# ESP32-S3 register map
Vendor: ESPRESSIF SYSTEMS (SHANGHAI) CO., LTD.; Series: ESP32 S-Series; File version: 22
CPU: Xtensa LX7 r0p0, little endian, no MPU, FPU, 0 interrupt priority bits
Address unit: 32 bits
Registers are 32-bit, read-write, reset 0x0 unless marked. A register's access mark holds for its fields unless they carry their own. Offsets are from the block's base; [hi:lo] are bit positions; {n}, {i} and the like mark numbered series.

## WCL — WCL Peripheral
Base 0x600D0000
0x00 Core_0_ENTRY_1_ADDR — Core_0 Entry 1 address configuration Register
  [31:0] CORE_0_ENTRY_1_ADDR — Core_0 Entry 1 address from WORLD1 to WORLD0
0x04 Core_0_ENTRY_2_ADDR — Core_0 Entry 2 address configuration Register
  [31:0] CORE_0_ENTRY_2_ADDR — Core_0 Entry 2 address from WORLD1 to WORLD0
0x08 Core_0_ENTRY_3_ADDR — Core_0 Entry 3 address configuration Register
  [31:0] CORE_0_ENTRY_3_ADDR — Core_0 Entry 3 address from WORLD1 to WORLD0
0x0C Core_0_ENTRY_4_ADDR — Core_0 Entry 4 address configuration Register
  [31:0] CORE_0_ENTRY_4_ADDR — Core_0 Entry 4 address from WORLD1 to WORLD0
0x10 Core_0_ENTRY_5_ADDR — Core_0 Entry 5 address configuration Register
  [31:0] CORE_0_ENTRY_5_ADDR — Core_0 Entry 5 address from WORLD1 to WORLD0
0x14 Core_0_ENTRY_6_ADDR — Core_0 Entry 6 address configuration Register
  [31:0] CORE_0_ENTRY_6_ADDR — Core_0 Entry 6 address from WORLD1 to WORLD0
0x18 Core_0_ENTRY_7_ADDR — Core_0 Entry 7 address configuration Register
  [31:0] CORE_0_ENTRY_7_ADDR — Core_0 Entry 7 address from WORLD1 to WORLD0
0x1C Core_0_ENTRY_8_ADDR — Core_0 Entry 8 address configuration Register
  [31:0] CORE_0_ENTRY_8_ADDR — Core_0 Entry 8 address from WORLD1 to WORLD0
0x20 Core_0_ENTRY_9_ADDR — Core_0 Entry 9 address configuration Register
  [31:0] CORE_0_ENTRY_9_ADDR — Core_0 Entry 9 address from WORLD1 to WORLD0
0x24 Core_0_ENTRY_10_ADDR — Core_0 Entry 10 address configuration Register
  [31:0] CORE_0_ENTRY_10_ADDR — Core_0 Entry 10 address from WORLD1 to WORLD0
0x28 Core_0_ENTRY_11_ADDR — Core_0 Entry 11 address configuration Register
  [31:0] CORE_0_ENTRY_11_ADDR — Core_0 Entry 11 address from WORLD1 to WORLD0
0x2C Core_0_ENTRY_12_ADDR — Core_0 Entry 12 address configuration Register
  [31:0] CORE_0_ENTRY_12_ADDR — Core_0 Entry 12 address from WORLD1 to WORLD0
0x30 Core_0_ENTRY_13_ADDR — Core_0 Entry 13 address configuration Register
  [31:0] CORE_0_ENTRY_13_ADDR — Core_0 Entry 13 address from WORLD1 to WORLD0
0x7C Core_0_ENTRY_CHECK reset 0x2 — Core_0 Entry check configuration Register
  [13:1] CORE_0_ENTRY_CHECK — This filed is used to enable entry address check
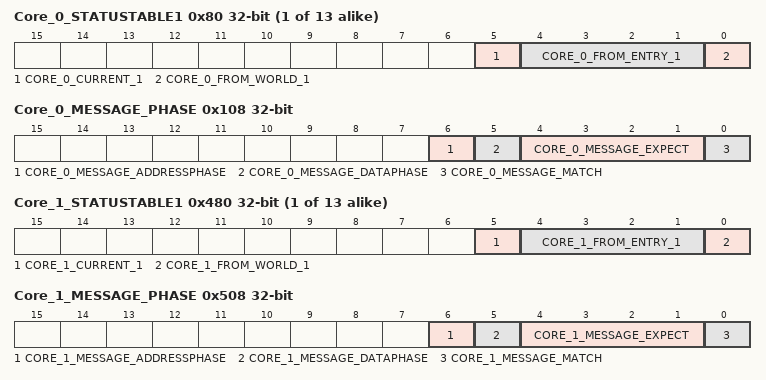
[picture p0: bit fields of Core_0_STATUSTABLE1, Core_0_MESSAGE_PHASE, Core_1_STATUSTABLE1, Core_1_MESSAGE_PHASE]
{0x7C+4i} Core_0_STATUSTABLE{i} (i=1..13) — Status register of world switch of entry {i}
  [5] CORE_0_CURRENT_{i} — This bit is used to confirm whether the current state is in entry {i}
  [4:1] CORE_0_FROM_ENTRY_{i} — This filed is used to confirm in which entry before enter entry {i}
  [0] CORE_0_FROM_WORLD_{i} — This bit is used to confirm world before enter entry {i}
0xFC Core_0_STATUSTABLE_CURRENT — Status register of statustable current
  [13:1] CORE_0_STATUSTABLE_CURRENT — This field is used to quickly read and rewrite the current field of all STATUSTABLE registers,for example,bit 1 represents the current field of STATUSTABLE1,bit2 represents the current field of STATUSTABLE2
0x100 Core_0_MESSAGE_ADDR — Clear writer_buffer write address configuration register
  [31:0] CORE_0_MESSAGE_ADDR — This field is used to set address that need to write when enter WORLD0
0x104 Core_0_MESSAGE_MAX — Clear writer_buffer write number configuration register
  [3:0] CORE_0_MESSAGE_MAX — This filed is used to set the max value of clear write_buffer
0x108 Core_0_MESSAGE_PHASE ro — Clear writer_buffer status register
  [6] CORE_0_MESSAGE_ADDRESSPHASE — If this bit is 1, it means that is checking clear write_buffer operation,and is checking address.
  [5] CORE_0_MESSAGE_DATAPHASE — If this bit is 1, it means that is checking clear write_buffer operation,and is checking data
  [4:1] CORE_0_MESSAGE_EXPECT — This field indicates the data to be written next time
  [0] CORE_0_MESSAGE_MATCH — This bit indicates whether the check is successful
0x140 Core_0_World_TRIGGER_ADDR — Core_0 trigger address configuration Register
  [31:0] CORE_0_WORLD_TRIGGER_ADDR — This field is used to configure the entry address from WORLD0 to WORLD1,when the CPU executes to this address,switch to WORLD1
0x144 Core_0_World_PREPARE — Core_0 prepare world configuration Register
  [1:0] CORE_0_WORLD_PREPARE — This field to used to set world to enter, 2'b01 means WORLD0, 2'b10 means WORLD1
0x148 Core_0_World_UPDATE wo — Core_0 configuration update register
  [31:0] CORE_0_UPDATE — This field is used to update configuration completed, can write any value,the hardware only checks the write operation of this register and does not case about its value
0x14C Core_0_World_Cancel wo — Core_0 configuration cancel register
  [31:0] CORE_0_WORLD_CANCEL — This field is used to cancel switch world configuration,if the trigger address and update configuration complete,use this register to cancel world switch, jujst need write any value,the hardware only checks the write operation of this register and does not case about its value
0x150 Core_0_World_IRam0 — Core_0 Iram0 world register
  [1:0] CORE_0_WORLD_IRAM0 — this field is used to read current world of Iram0 bus
0x154 Core_0_World_DRam0_PIF — Core_0 dram0 and PIF world register
  [1:0] CORE_0_WORLD_DRAM0_PIF — this field is used to read current world of Dram0 bus and PIF bus
0x158 Core_0_World_Phase ro — Core_0 world status register
  [0] CORE_0_WORLD_PHASE — This bit indicates whether is preparing to switch to WORLD1, 1 means value.
0x180 Core_0_NMI_MASK_ENABLE wo
  [31:0] CORE_0_NMI_MASK_ENABLE — this field is used to set NMI mask,it can write any value,when write this register,the hardware start masking NMI interrupt
0x184 Core_0_NMI_MASK_TRIGGER_ADDR — Core_0 NMI mask trigger address register
  [31:0] CORE_0_NMI_MASK_TRIGGER_ADDR — this field to used to set trigger address, when CPU executes to this address,NMI mask automatically fails
0x188 Core_0_NMI_MASK_DISABLE wo
  [31:0] CORE_0_NMI_MASK_DISABLE — this field is used to disable NMI mask,it will not take effect immediately,only when the CPU executes to the trigger address will it start to cancel NMI mask
0x18C Core_0_NMI_MASK_CANCLE wo — Core_0 NMI mask disable register
  [31:0] CORE_0_NMI_MASK_CANCEL — this field is used to cancel NMI mask disable function.
0x190 Core_0_NMI_MASK
  [0] CORE_0_NMI_MASK — this bit is used to mask NMI interrupt,it can directly mask NMI interrupt
0x194 Core_0_NMI_MASK_PHASE ro
  [0] CORE_0_NMI_MASK_PHASE — this bit is used to indicates whether the NMI interrupt is being masked, 1 means NMI interrupt is being masked
{0x3FC+4i} Core_1_ENTRY_{i}_ADDR (i=1..13) — Core_1 Entry {i} address configuration Register
  [31:0] CORE_1_ENTRY_{i}_ADDR — Core_1 Entry {i} address from WORLD1 to WORLD0
0x47C Core_1_ENTRY_CHECK reset 0x2 — Core_1 Entry check configuration Register
  [13:1] CORE_1_ENTRY_CHECK — This filed is used to enable entry address check
{0x47C+4i} Core_1_STATUSTABLE{i} (i=1..13) — Status register of world switch of entry {i}
  [5] CORE_1_CURRENT_{i} — This bit is used to confirm whether the current state is in entry {i}
  [4:1] CORE_1_FROM_ENTRY_{i} — This filed is used to confirm in which entry before enter entry {i}
  [0] CORE_1_FROM_WORLD_{i} — This bit is used to confirm world before enter entry {i}
0x4FC Core_1_STATUSTABLE_CURRENT — Status register of statustable current
  [13:1] CORE_1_STATUSTABLE_CURRENT — This field is used to quickly read and rewrite the current field of all STATUSTABLE registers,for example,bit 1 represents the current field of STATUSTABLE1
0x500 Core_1_MESSAGE_ADDR — Clear writer_buffer write address configuration register
  [31:0] CORE_1_MESSAGE_ADDR — This field is used to set address that need to write when enter WORLD0
0x504 Core_1_MESSAGE_MAX — Clear writer_buffer write number configuration register
  [3:0] CORE_1_MESSAGE_MAX — This filed is used to set the max value of clear write_buffer
0x508 Core_1_MESSAGE_PHASE ro — Clear writer_buffer status register
  [6] CORE_1_MESSAGE_ADDRESSPHASE — If this bit is 1, it means that is checking clear write_buffer operation, and is checking address.
  [5] CORE_1_MESSAGE_DATAPHASE — If this bit is 1, it means that is checking clear write_buffer operation, and is checking data
  [4:1] CORE_1_MESSAGE_EXPECT — This field indicates the data to be written next time
  [0] CORE_1_MESSAGE_MATCH — This bit indicates whether the check is successful
0x540 Core_1_World_TRIGGER_ADDR — Core_1 trigger address configuration Register
  [31:0] CORE_1_WORLD_TRIGGER_ADDR — This field is used to configure the entry address from WORLD0 to WORLD1,when the CPU executes to this address,switch to WORLD1
0x544 Core_1_World_PREPARE — Core_1 prepare world configuration Register
  [1:0] CORE_1_WORLD_PREPARE — This field to used to set world to enter,2'b01 means WORLD0, 2'b10 means WORLD1
0x548 Core_1_World_UPDATE wo — Core_1 configuration update register
  [31:0] CORE_1_UPDATE — This field is used to update configuration completed, can write any value,the hardware only checks the write operation of this register and does not case about its value
0x54C Core_1_World_Cancel wo — Core_1 configuration cancel register
  [31:0] CORE_1_WORLD_CANCEL — This field is used to cancel switch world configuration,if the trigger address and update configuration complete,can use this register to cancel world switch. can write any value, the hardware only checks the write operation of this register and does not case about its value
0x550 Core_1_World_IRam0 — Core_1 Iram0 world register
  [1:0] CORE_1_WORLD_IRAM0 — this field is used to read current world of Iram0 bus
0x554 Core_1_World_DRam0_PIF — Core_1 dram0 and PIF world register
  [1:0] CORE_1_WORLD_DRAM0_PIF — this field is used to read current world of Dram0 bus and PIF bus
0x558 Core_1_World_Phase ro — Core_0 world status register
  [0] CORE_1_WORLD_PHASE — This bit indicates whether is preparing to switch to WORLD1,1 means value.
0x580 Core_1_NMI_MASK_ENABLE wo
  [31:0] CORE_1_NMI_MASK_ENABLE — this field is used to set NMI mask, it can write any value, when write this register,the hardware start masking NMI interrupt
0x584 Core_1_NMI_MASK_TRIGGER_ADDR
  [31:0] CORE_1_NMI_MASK_TRIGGER_ADDR — this field to used to set trigger address
0x588 Core_1_NMI_MASK_DISABLE wo
  [31:0] CORE_1_NMI_MASK_DISABLE — this field is used to disable NMI mask, it will not take effect immediately,only when the CPU executes to the trigger address will it start to cancel NMI mask
0x58C Core_1_NMI_MASK_CANCLE wo — Core_1 NMI mask disable register
  [31:0] CORE_1_NMI_MASK_CANCEL — this field is used to cancel NMI mask disable function.
0x590 Core_1_NMI_MASK
  [0] CORE_1_NMI_MASK — this bit is used to mask NMI interrupt,it can directly mask NMI interrupt
0x594 Core_1_NMI_MASK_PHASE ro
  [0] CORE_1_NMI_MASK_PHASE — this bit is used to indicates whether the NMI interrupt is being masked, 1 means NMI interrupt is being masked
